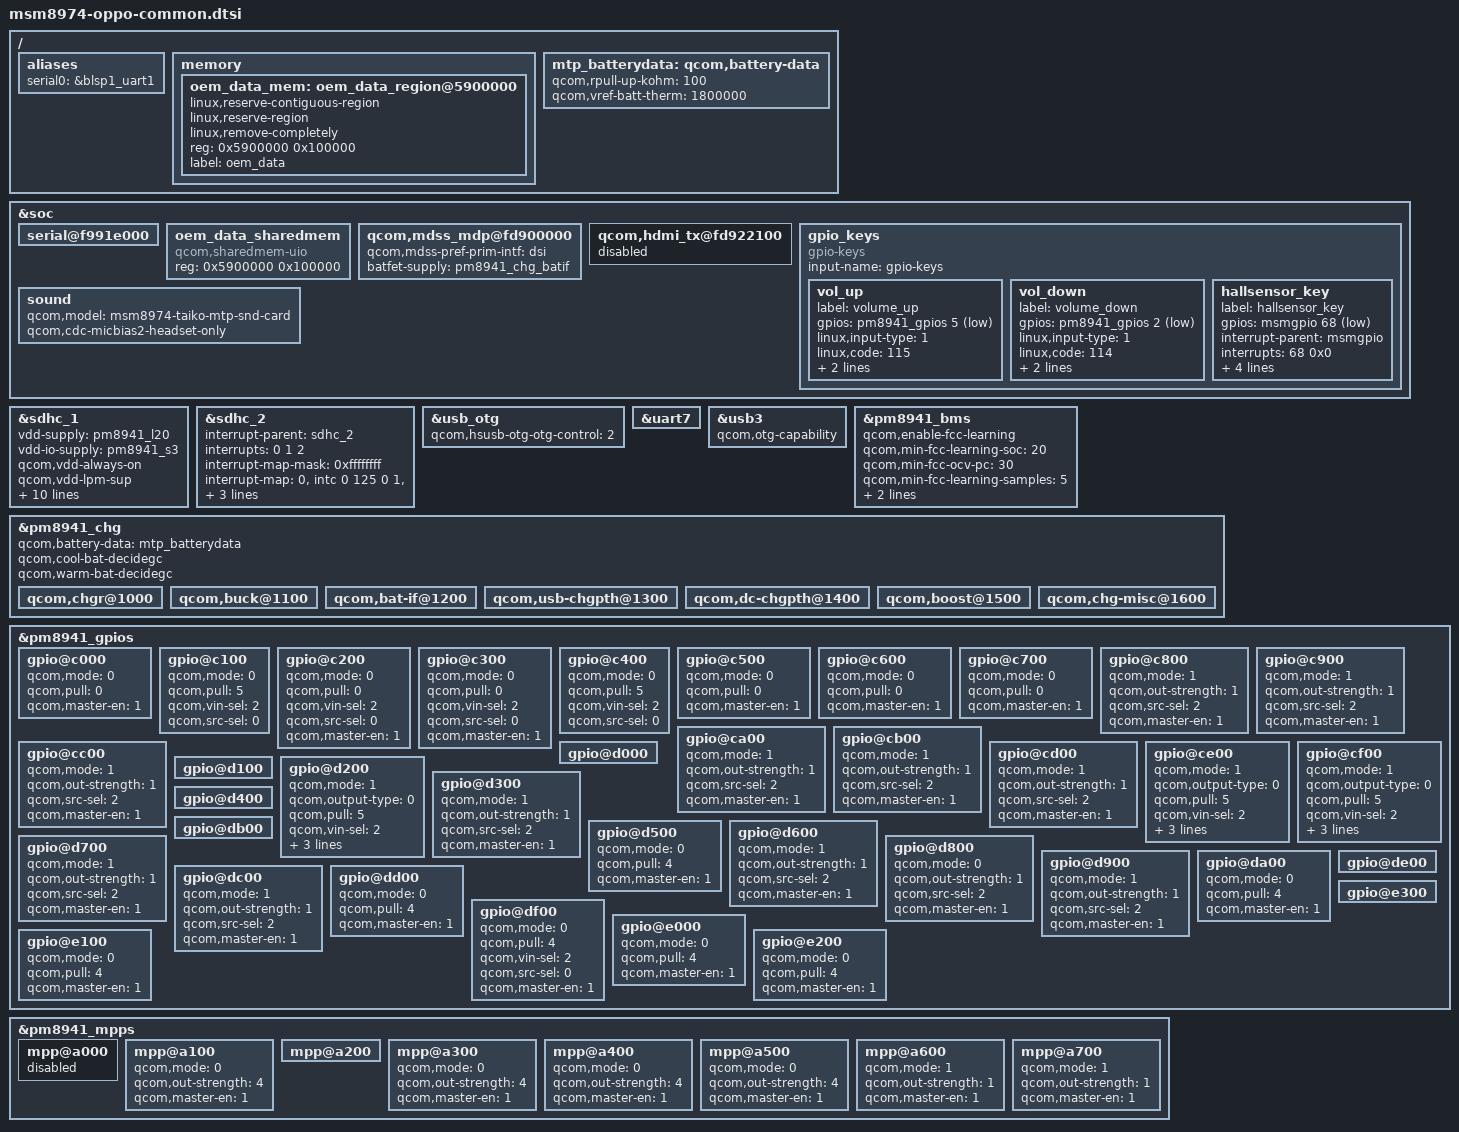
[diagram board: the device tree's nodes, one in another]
/* Copyright (c) 2012-2013, The Linux Foundation. All rights reserved.
 *
 * This program is free software; you can redistribute it and/or modify
 * it under the terms of the GNU General Public License version 2 and
 * only version 2 as published by the Free Software Foundation.
 *
 * This program is distributed in the hope that it will be useful,
 * but WITHOUT ANY WARRANTY; without even the implied warranty of
 * MERCHANTABILITY or FITNESS FOR A PARTICULAR PURPOSE.  See the
 * GNU General Public License for more details.
 */

/include/ "msm8974-oppo-panel.dtsi"

/ {
	aliases {
		serial0 = &blsp1_uart1;
	};

	memory {
		oem_data_mem: oem_data_region@5900000 {
			linux,reserve-contiguous-region;
			linux,reserve-region;
			linux,remove-completely;
			reg = <0x5900000 0x100000>;
			label = "oem_data";
		};
	};
};

&soc {
	serial@f991e000 {
		status = "ok";
	};

	oem_data_sharedmem {
		compatible = "qcom,sharedmem-uio";
		reg = <0x5900000 0x100000>;
		reg-names = "oem_data";
	};

	qcom,mdss_mdp@fd900000 {
		qcom,mdss-pref-prim-intf = "dsi";
		batfet-supply = <&pm8941_chg_batif>;
	};

	qcom,hdmi_tx@fd922100 {
		status = "disabled";
	};

	gpio_keys {
		compatible = "gpio-keys";
		input-name = "gpio-keys";
		status = "ok";

		vol_up {
			label = "volume_up";
			gpios = <&pm8941_gpios 5 0x1>;
			linux,input-type = <1>;
			linux,code = <115>;
			gpio-key,wakeup;
			debounce-interval = <15>;
		};

		vol_down {
			label = "volume_down";
			gpios = <&pm8941_gpios 2 0x1>;
			linux,input-type = <1>;
			linux,code = <114>;
			gpio-key,wakeup;
			debounce-interval = <15>;
		};

		hallsensor_key {
			label = "hallsensor_key";
			gpios = <&msmgpio 68 1>;
			interrupt-parent = <&msmgpio>;
			interrupts = <68 0x0>;
			linux,input-type = <5>;
			linux,code = <0>;
			gpio-key,wakeup;
			debounce-interval = <150>;
		};
	};

	sound {
		qcom,model = "msm8974-taiko-mtp-snd-card";
		qcom,cdc-micbias2-headset-only;
	};
};

&sdhc_1 {
	vdd-supply = <&pm8941_l20>;
	vdd-io-supply = <&pm8941_s3>;

	qcom,vdd-always-on;
	qcom,vdd-lpm-sup;
	qcom,vdd-voltage-level = <2950000 2950000>;
	qcom,vdd-current-level = <800 500000>;

	qcom,vdd-io-always-on;
	qcom,vdd-io-voltage-level = <1800000 1800000>;
	qcom,vdd-io-current-level = <250 154000>;

	qcom,pad-pull-on = <0x0 0x3 0x3>; /* no-pull, pull-up, pull-up */
	qcom,pad-pull-off = <0x0 0x3 0x3>; /* no-pull, pull-up, pull-up */
	qcom,pad-drv-on = <0x4 0x4 0x4>; /* 10mA, 10mA, 10mA */
	qcom,pad-drv-off = <0x0 0x0 0x0>; /* 2mA, 2mA, 2mA */

	qcom,nonremovable;
	status = "ok";
};

&sdhc_2 {
	#address-cells = <0>;
	interrupt-parent = <&sdhc_2>;
	interrupts = <0 1 2>;
	#interrupt-cells = <1>;
	interrupt-map-mask = <0xffffffff>;
	interrupt-map = <0 &intc 0 125 0
			1 &intc 0 221 0
			2 &msmgpio 69 0x3>;
	interrupt-names = "hc_irq", "pwr_irq", "status_irq";

	qcom,nonremovable;
	/delete-property/ cd-gpios;
};

/* Drive strength recommendations for clock line from hardware team is 10 mA.
 * But since the driver has been been using the below values from the start
 * without any problems, continue to use those.
 */
&sdhc_1 {
	qcom,pad-drv-on = <0x7 0x4 0x4>; /* 16mA, 10mA, 10mA */
};

&sdhc_2 {
	qcom,pad-drv-on = <0x7 0x4 0x4>; /* 16mA, 10mA, 10mA */
};

&usb_otg {
	qcom,hsusb-otg-otg-control = <2>;
};

&uart7 {
	status = "ok";
};

&usb3 {
	qcom,otg-capability;
};

/ {
	mtp_batterydata: qcom,battery-data {
		qcom,rpull-up-kohm = <100>;
		qcom,vref-batt-therm = <1800000>;

		/include/ "../batterydata-palladium.dtsi"
		/include/ "../batterydata-mtp-3000mah.dtsi"
	};
};

&pm8941_bms {
	qcom,enable-fcc-learning;
	qcom,min-fcc-learning-soc = <20>;
	qcom,min-fcc-ocv-pc = <30>;
	qcom,min-fcc-learning-samples = <5>;
	qcom,fcc-resolution = <10>;
	status = "ok";
	qcom,battery-data = <&mtp_batterydata>;
};

&pm8941_chg {
	status = "ok";
	qcom,battery-data = <&mtp_batterydata>;
	qcom,cool-bat-decidegc;
	qcom,warm-bat-decidegc;

	qcom,chgr@1000 {
		status = "ok";
	};

	qcom,buck@1100 {
		status = "ok";
	};

	qcom,bat-if@1200 {
		status = "ok";
	};

	qcom,usb-chgpth@1300 {
		status = "ok";
	};

	qcom,dc-chgpth@1400 {
		status = "ok";
	};

	qcom,boost@1500 {
		status = "ok";
	};

	qcom,chg-misc@1600 {
		status = "ok";
	};
};

&pm8941_gpios {
	gpio@c000 { /* GPIO 1 */
		qcom,mode = <0>;        /* QPNP_PIN_MODE_DIG_IN */
		qcom,pull = <0>;        /* QPNP_PIN_PULL_UP_30  */
		qcom,master-en = <1>;
	};

	gpio@c100 { /* GPIO 2 */
		qcom,mode = <0>;        /* QPNP_PIN_MODE_DIG_IN */
		qcom,pull = <5>;        /* QPNP_PIN_PULL_UP_30  */
		qcom,vin-sel = <2>;
		qcom,src-sel = <0>;
	};

	gpio@c200 { /* GPIO 3 */
		qcom,mode = <0>;        /* QPNP_PIN_MODE_DIG_IN */
		qcom,pull = <0>;        /* QPNP_PIN_PULL_UP_30  */
		qcom,vin-sel = <2>;
		qcom,src-sel = <0>;	/* QPNP_PIN_SEL_FUNC_CONSTANT */
		qcom,master-en = <1>;
	};

	gpio@c300 { /* GPIO 4 */
		qcom,mode = <0>;        /* QPNP_PIN_MODE_DIG_IN */
		qcom,pull = <0>;        /* QPNP_PIN_PULL_UP_30  */
		qcom,vin-sel = <2>;     /* QPNP_PIN_VIN2  */
		qcom,src-sel = <0>;	/* QPNP_PIN_SEL_FUNC_CONSTANT */
		qcom,master-en = <1>;
	};

	gpio@c400 { /* GPIO 5 */
		qcom,mode = <0>;        /* QPNP_PIN_MODE_DIG_IN */
		qcom,pull = <5>;        /* QPNP_PIN_PULL_UP_30  */
		qcom,vin-sel = <2>;     /* QPNP_PIN_VIN2  */
		qcom,src-sel = <0>;	/* QPNP_PIN_SEL_FUNC_CONSTANT */
	};

	gpio@c500 { /* GPIO 6 */
		qcom,mode = <0>;        /* QPNP_PIN_MODE_DIG_IN */
		qcom,pull = <0>;        /* QPNP_PIN_PULL_UP_30  */
		qcom,master-en = <1>;
	};

	gpio@c600 { /* GPIO 7 */
		qcom,mode = <0>;        /* QPNP_PIN_MODE_DIG_IN */
		qcom,pull = <0>;        /* QPNP_PIN_PULL_UP_30  */
		qcom,master-en = <1>;
	};

	gpio@c700 { /* GPIO 8 */
		qcom,mode = <0>;        /* QPNP_PIN_MODE_DIG_IN */
		qcom,pull = <0>;        /* QPNP_PIN_PULL_UP_30  */
		qcom,master-en = <1>;
	};

	gpio@c800 { /* GPIO 9 */
		qcom,mode = <1>;          /* QPNP_PIN_MODE_DIG_OUT */
		qcom,out-strength = <1>;  /* QPNP_PIN_OUT_STRENGTH_LOW */
		qcom,src-sel = <2>;       /* QPNP_PIN_SEL_FUNC_1  */
		qcom,master-en = <1>;
	};

	gpio@c900 { /* GPIO 10 */
		qcom,mode = <1>;          /* QPNP_PIN_MODE_DIG_OUT */
		qcom,out-strength = <1>;  /* QPNP_PIN_OUT_STRENGTH_LOW */
		qcom,src-sel = <2>;       /* QPNP_PIN_SEL_FUNC_1  */
		qcom,master-en = <1>;
	};

	gpio@ca00 { /* GPIO 11 */
		qcom,mode = <1>;          /* QPNP_PIN_MODE_DIG_OUT */
		qcom,out-strength = <1>;  /* QPNP_PIN_OUT_STRENGTH_LOW */
		qcom,src-sel = <2>;       /* QPNP_PIN_SEL_FUNC_1  */
		qcom,master-en = <1>;
	};

	gpio@cb00 { /* GPIO 12 */
		qcom,mode = <1>;          /* QPNP_PIN_MODE_DIG_OUT */
		qcom,out-strength = <1>;  /* QPNP_PIN_OUT_STRENGTH_LOW */
		qcom,src-sel = <2>;       /* QPNP_PIN_SEL_FUNC_1  */
		qcom,master-en = <1>;
	};

	gpio@cc00 { /* GPIO 13 */
		qcom,mode = <1>;          /* QPNP_PIN_MODE_DIG_OUT */
		qcom,out-strength = <1>;  /* QPNP_PIN_OUT_STRENGTH_LOW */
		qcom,src-sel = <2>;       /* QPNP_PIN_SEL_FUNC_1  */
		qcom,master-en = <1>;
	};

	gpio@cd00 { /* GPIO 14 */
		qcom,mode = <1>;          /* QPNP_PIN_MODE_DIG_OUT */
		qcom,out-strength = <1>;  /* QPNP_PIN_OUT_STRENGTH_LOW */
		qcom,src-sel = <2>;       /* QPNP_PIN_SEL_FUNC_1  */
		qcom,master-en = <1>;
	};

	gpio@ce00 { /* GPIO 15 */
		qcom,mode = <1>;
		qcom,output-type = <0>;
		qcom,pull = <5>;
		qcom,vin-sel = <2>;
		qcom,out-strength = <1>;
		qcom,src-sel = <2>;
		qcom,master-en = <1>;
	};

	gpio@cf00 { /* GPIO 16 */
		qcom,mode = <1>;
		qcom,output-type = <0>;
		qcom,pull = <5>;
		qcom,vin-sel = <2>;
		qcom,out-strength = <1>;
		qcom,src-sel = <2>;       /* QPNP_PIN_SEL_FUNC_2  */
		qcom,master-en = <1>;
	};

	gpio@d000 { /* GPIO 17 */
	};

	gpio@d100 { /* GPIO 18 */
	};

	gpio@d200 { /* GPIO 19 */
		qcom,mode = <1>;		/* QPNP_PIN_MODE_DIG_OUT */
		qcom,output-type = <0>;		/* QPNP_PIN_OUT_BUF_CMOS */
		qcom,pull = <5>;		/* QPNP_PIN_PULL_NO */
		qcom,vin-sel = <2>;		/* QPNP_PIN_VIN2 */
		qcom,out-strength = <1>;	/* QPNP_PIN_OUT_STRENGTH_LOW */
		qcom,src-sel = <0>;		/* QPNP_PIN_SEL_FUNC_CONSTANT */
		qcom,master-en = <1>;
	};

	gpio@d300 { /* GPIO 20 */
		qcom,mode = <1>;          /* QPNP_PIN_MODE_DIG_OUT */
		qcom,out-strength = <1>;  /* QPNP_PIN_OUT_STRENGTH_LOW */
		qcom,src-sel = <2>;       /* QPNP_PIN_SEL_FUNC_1  */
		qcom,master-en = <1>;
	};

	gpio@d400 { /* GPIO 21 */
	};

	gpio@d500 { /* GPIO 22 */
		qcom,mode = <0>;        /* QPNP_PIN_MODE_DIG_IN */
		qcom,pull = <4>;	/* QPNP_PIN_PULL_DN */
		qcom,master-en = <1>;
	};

	gpio@d600 { /* GPIO 23 */
		qcom,mode = <1>;          /* QPNP_PIN_MODE_DIG_OUT */
		qcom,out-strength = <1>;  /* QPNP_PIN_OUT_STRENGTH_LOW */
		qcom,src-sel = <2>;       /* QPNP_PIN_SEL_FUNC_1  */
		qcom,master-en = <1>;
	};

	gpio@d700 { /* GPIO 24 */
		qcom,mode = <1>;          /* QPNP_PIN_MODE_DIG_OUT */
		qcom,out-strength = <1>;  /* QPNP_PIN_OUT_STRENGTH_LOW */
		qcom,src-sel = <2>;       /* QPNP_PIN_SEL_FUNC_1  */
		qcom,master-en = <1>;
	};

	gpio@d800 { /* GPIO 25 */
		qcom,mode = <0>;          /* QPNP_PIN_MODE_DIG_OUT */
		qcom,out-strength = <1>;  /* QPNP_PIN_OUT_STRENGTH_LOW */
		qcom,src-sel = <2>;       /* QPNP_PIN_SEL_FUNC_1  */
		qcom,master-en = <1>;
	};

	gpio@d900 { /* GPIO 26 */
		qcom,mode = <1>;          /* QPNP_PIN_MODE_DIG_OUT */
		qcom,out-strength = <1>;  /* QPNP_PIN_OUT_STRENGTH_LOW */
		qcom,src-sel = <2>;       /* QPNP_PIN_SEL_FUNC_1  */
		qcom,master-en = <1>;
	};

	gpio@da00 { /* GPIO 27 */
		qcom,mode = <0>;        /* QPNP_PIN_MODE_DIG_IN */
		qcom,pull = <4>;	/* QPNP_PIN_PULL_DN */
		qcom,master-en = <1>;
	};

	gpio@db00 { /* GPIO 28 */
	};

	gpio@dc00 { /* GPIO 29 */
		qcom,mode = <1>;          /* QPNP_PIN_MODE_DIG_OUT */
		qcom,out-strength = <1>;  /* QPNP_PIN_OUT_STRENGTH_LOW */
		qcom,src-sel = <2>;       /* QPNP_PIN_SEL_FUNC_1  */
		qcom,master-en = <1>;
	};

	gpio@dd00 { /* GPIO 30 */
		qcom,mode = <0>;        /* QPNP_PIN_MODE_DIG_IN */
		qcom,pull = <4>;	/* QPNP_PIN_PULL_DN */
		qcom,master-en = <1>;
	};

	gpio@de00 { /* GPIO 31 */
	};

	gpio@df00 { /* GPIO 32 */
		qcom,mode = <0>;        /* QPNP_PIN_MODE_DIG_IN */
		qcom,pull = <4>;	/* QPNP_PIN_PULL_DN */
		qcom,vin-sel = <2>;
		qcom,src-sel = <0>;	/* QPNP_PIN_SEL_FUNC_CONSTANT */
		qcom,master-en = <1>;
	};

	gpio@e000 { /* GPIO 33 */
		qcom,mode = <0>;        /* QPNP_PIN_MODE_DIG_IN */
		qcom,pull = <4>;	/* QPNP_PIN_PULL_DN */
		qcom,master-en = <1>;
	};

	gpio@e100 { /* GPIO 34 */
		qcom,mode = <0>;        /* QPNP_PIN_MODE_DIG_IN */
		qcom,pull = <4>;	/* QPNP_PIN_PULL_DN */
		qcom,master-en = <1>;
	};

	gpio@e200 { /* GPIO 35 */
		qcom,mode = <0>;        /* QPNP_PIN_MODE_DIG_IN */
		qcom,pull = <4>;	/* QPNP_PIN_PULL_DN */
		qcom,master-en = <1>;
	};

	gpio@e300 { /* GPIO 36 */
	};
};

&pm8941_mpps {

	mpp@a000 { /* MPP 1 */
		status = "disabled";
	};

	mpp@a100 { /* MPP 2 */
		qcom,mode = <0>;          /* QPNP_PIN_MODE_DIG_IN */
		qcom,out-strength = <4>;  /* QPNP_PIN_PULL_DN */
		qcom,master-en = <1>;
	};

	mpp@a200 { /* MPP 3 */
	};

	mpp@a300 { /* MPP 4 */
		qcom,mode = <0>;          /* QPNP_PIN_MODE_DIG_IN */
		qcom,out-strength = <4>;  /* QPNP_PIN_PULL_DN */
		qcom,master-en = <1>;
	};

	mpp@a400 { /* MPP 5 */
		qcom,mode = <0>;          /* QPNP_PIN_MODE_DIG_IN */
		qcom,out-strength = <4>;  /* QPNP_PIN_PULL_DN */
		qcom,master-en = <1>;
	};

	mpp@a500 { /* MPP 6 */
		qcom,mode = <0>;          /* QPNP_PIN_MODE_DIG_IN */
		qcom,out-strength = <4>;  /* QPNP_PIN_PULL_DN */
		qcom,master-en = <1>;
	};

	mpp@a600 { /* MPP 7 */
		qcom,mode = <1>;          /* QPNP_PIN_MODE_DIG_OUT */
		qcom,out-strength = <1>;  /* QPNP_PIN_OUT_STRENGTH_LOW */
		qcom,master-en = <1>;
	};

	mpp@a700 { /* MPP 8 */
		qcom,mode = <1>;          /* QPNP_PIN_MODE_DIG_OUT */
		qcom,out-strength = <1>;  /* QPNP_PIN_OUT_STRENGTH_LOW */
		qcom,master-en = <1>;
	};
};
